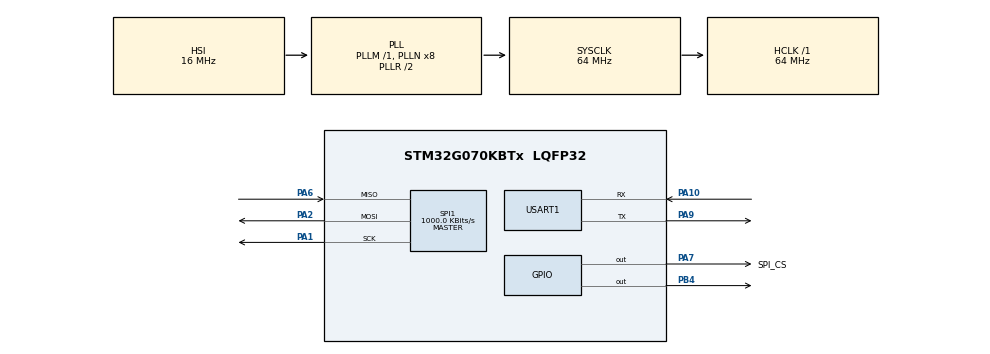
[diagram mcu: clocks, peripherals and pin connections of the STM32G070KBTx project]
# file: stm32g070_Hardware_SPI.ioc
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Dma.Request0=USART1_RX
Dma.Request1=USART1_TX
Dma.USART1_RX.0.Direction=DMA_PERIPH_TO_MEMORY
Dma.USART1_RX.0.EventEnable=DISABLE
Dma.USART1_RX.0.Instance=DMA1_Channel1
Dma.USART1_RX.0.MemDataAlignment=DMA_MDATAALIGN_BYTE
Dma.USART1_RX.0.MemInc=DMA_MINC_ENABLE
Dma.USART1_RX.0.Mode=DMA_CIRCULAR
Dma.USART1_RX.0.PeriphDataAlignment=DMA_PDATAALIGN_BYTE
Dma.USART1_RX.0.PeriphInc=DMA_PINC_DISABLE
Dma.USART1_RX.0.Polarity=HAL_DMAMUX_REQ_GEN_RISING
Dma.USART1_RX.0.Priority=DMA_PRIORITY_MEDIUM
Dma.USART1_RX.0.RequestNumber=1
Dma.USART1_RX.0.SignalID=NONE
Dma.USART1_RX.0.SyncEnable=DISABLE
Dma.USART1_RX.0.SyncPolarity=HAL_DMAMUX_SYNC_NO_EVENT
Dma.USART1_RX.0.SyncRequestNumber=1
Dma.USART1_RX.0.SyncSignalID=NONE
Dma.USART1_TX.1.Direction=DMA_MEMORY_TO_PERIPH
Dma.USART1_TX.1.EventEnable=DISABLE
Dma.USART1_TX.1.Instance=DMA1_Channel2
Dma.USART1_TX.1.MemDataAlignment=DMA_MDATAALIGN_BYTE
Dma.USART1_TX.1.MemInc=DMA_MINC_ENABLE
Dma.USART1_TX.1.Mode=DMA_NORMAL
Dma.USART1_TX.1.PeriphDataAlignment=DMA_PDATAALIGN_BYTE
Dma.USART1_TX.1.PeriphInc=DMA_PINC_DISABLE
Dma.USART1_TX.1.Polarity=HAL_DMAMUX_REQ_GEN_RISING
Dma.USART1_TX.1.Priority=DMA_PRIORITY_MEDIUM
Dma.USART1_TX.1.RequestNumber=1
Dma.USART1_TX.1.SignalID=NONE
Dma.USART1_TX.1.SyncEnable=DISABLE
Dma.USART1_TX.1.SyncPolarity=HAL_DMAMUX_SYNC_NO_EVENT
Dma.USART1_TX.1.SyncRequestNumber=1
Dma.USART1_TX.1.SyncSignalID=NONE
Mcu.Family=STM32G0
Mcu.Name=STM32G070KBTx
Mcu.Package=LQFP32
NVIC.DMA1_Channel1_IRQn=true\:0\:0\:false\:false\:true\:false\:true
NVIC.DMA1_Channel2_3_IRQn=true\:0\:0\:false\:false\:true\:false\:true
NVIC.USART1_IRQn=true\:0\:0\:false\:false\:true\:true\:true
PA1.GPIO_Mode=GPIO_MODE_AF_PP
PA1.GPIO_PuPd=GPIO_NOPULL
PA1.GPIO_Speed=GPIO_SPEED_FREQ_VERY_HIGH
PA1.Mode=Full_Duplex_Master
PA1.PinState=GPIO_PIN_RESET
PA1.Signal=SPI1_SCK
PA10.Mode=Asynchronous
PA10.Signal=USART1_RX
PA13.Mode=Serial_Wire
PA13.Signal=SYS_SWDIO
PA14-BOOT0.Mode=Serial_Wire
PA14-BOOT0.Signal=SYS_SWCLK
PA2.GPIO_Mode=GPIO_MODE_AF_PP
PA2.GPIO_PuPd=GPIO_NOPULL
PA2.GPIO_Speed=GPIO_SPEED_FREQ_VERY_HIGH
PA2.Mode=Full_Duplex_Master
PA2.PinState=GPIO_PIN_RESET
PA2.Signal=SPI1_MOSI
PA6.GPIO_Mode=GPIO_MODE_AF_PP
PA6.GPIO_PuPd=GPIO_NOPULL
PA6.GPIO_Speed=GPIO_SPEED_FREQ_VERY_HIGH
PA6.Mode=Full_Duplex_Master
PA6.PinState=GPIO_PIN_RESET
PA6.Signal=SPI1_MISO
PA7.GPIO_Label=SPI_CS
PA7.GPIO_Speed=GPIO_SPEED_FREQ_HIGH
PA7.Signal=GPIO_Output
PA9.Mode=Asynchronous
PA9.Signal=USART1_TX
PB4.GPIO_ModeDefaultOutputPP=GPIO_MODE_OUTPUT_PP
PB4.GPIO_PuPd=GPIO_NOPULL
PB4.GPIO_Speed=GPIO_SPEED_FREQ_LOW
PB4.PinState=GPIO_PIN_RESET
PB4.Signal=GPIO_Output
PC14-OSC32_IN\ (PC14).Mode=LSE-External-Oscillator
PC14-OSC32_IN\ (PC14).Signal=RCC_OSC32_IN
PC15-OSC32_OUT\ (PC15).Mode=LSE-External-Oscillator
PC15-OSC32_OUT\ (PC15).Signal=RCC_OSC32_OUT
ProjectManager.HeapSize=0x200
ProjectManager.StackSize=0x400
ProjectManager.TargetToolchain=Makefile
RCC.ADCFreq_Value=64000000
RCC.AHBFreq_Value=64000000
RCC.CortexFreq_Value=64000000
RCC.EXTERNAL_CLOCK_VALUE=48000
RCC.HCLKFreq_Value=64000000
RCC.HSE_VALUE=8000000
RCC.HSI_VALUE=16000000
RCC.SYSCLKFreq_VALUE=64000000
RCC.SYSCLKSource=RCC_SYSCLKSOURCE_PLLCLK
RCC.VCOOutputFreq_Value=128000000
SPI1.BaudRatePrescaler=SPI_BAUDRATEPRESCALER_64
SPI1.CalculateBaudRate=1000.0 KBits/s
SPI1.DataSize=SPI_DATASIZE_8BIT
SPI1.Direction=SPI_DIRECTION_2LINES
SPI1.Mode=SPI_MODE_MASTER
SPI1.VirtualType=VM_MASTER
USART1.VirtualMode-Asynchronous=VM_ASYNC
VP_SYS_VS_DBSignals.Mode=DisableDeadBatterySignals
board=custom

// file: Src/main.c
/* USER CODE BEGIN Header */
/**
  ******************************************************************************
  * @file           : main.c
  * @brief          : Main program body
  ******************************************************************************
  * @attention
  *
  * <h2><center>&copy; Copyright (c) 2020 STMicroelectronics.
  * All rights reserved.</center></h2>
  *
  * This software component is licensed by ST under BSD 3-Clause license,
  * the "License"; You may not use this file except in compliance with the
  * License. You may obtain a copy of the License at:
  *                        opensource.org/licenses/BSD-3-Clause
  *
  ******************************************************************************
  */
/* USER CODE END Header */

#include "main.h"
#include "dma.h"
#include "spi.h"
#include "usart.h"
#include "gpio.h"

/* USER CODE BEGIN Includes */
#include "oled.h"
/* USER CODE END Includes */

/* USER CODE BEGIN PV */
uint8_t Data[2]={0x55,0xaa};

/* USER CODE END PV */

void SystemClock_Config(void);

int main(void)
{

  /* MCU Configuration--------------------------------------------------------*/

  /* Reset of all peripherals, Initializes the Flash interface and the Systick. */
  HAL_Init();

  /* Configure the system clock */
  SystemClock_Config();

  /* Initialize all configured peripherals */
  MX_GPIO_Init();
  MX_DMA_Init();
  MX_SPI1_Init();
  MX_USART1_UART_Init();
  /* USER CODE BEGIN 2 */
	OLED_Init();
	OLED_Clear();
	OLED_ShowString(0,0,"receive:",16);
  /* USER CODE END 2 */

  /* Infinite loop */
  /* USER CODE BEGIN WHILE */
	//HAL_SPI_Transmit(&hspi1,Data,1,1000);//发送数据
  while (1)
  {
    /* USER CODE END WHILE */

    /* USER CODE BEGIN 3 */

	HAL_GPIO_WritePin(GPIOA,SPI_CS_Pin,GPIO_PIN_SET);		//片选使能

	HAL_SPI_Transmit(&hspi1,&Data[0],1,100);//发送数据
	HAL_SPI_Receive(&hspi1,&Data[1],1,0xFFFF);//接收数据
	OLED_ShowNum(72,0,Data[1],3,16);
	HAL_GPIO_TogglePin(GPIOB,GPIO_PIN_4);
	HAL_GPIO_WritePin(GPIOA,SPI_CS_Pin,GPIO_PIN_RESET);  	//片选不使能
	HAL_Delay(500);

  }
  /* USER CODE END 3 */
}

void SystemClock_Config(void)
{
  RCC_OscInitTypeDef RCC_OscInitStruct = {0};
  RCC_ClkInitTypeDef RCC_ClkInitStruct = {0};
  RCC_PeriphCLKInitTypeDef PeriphClkInit = {0};

  /** Configure the main internal regulator output voltage
  */
  HAL_PWREx_ControlVoltageScaling(PWR_REGULATOR_VOLTAGE_SCALE1);
  /** Initializes the CPU, AHB and APB busses clocks
  */
  RCC_OscInitStruct.OscillatorType = RCC_OSCILLATORTYPE_HSI;
  RCC_OscInitStruct.HSIState = RCC_HSI_ON;
  RCC_OscInitStruct.HSIDiv = RCC_HSI_DIV1;
  RCC_OscInitStruct.HSICalibrationValue = RCC_HSICALIBRATION_DEFAULT;
  RCC_OscInitStruct.PLL.PLLState = RCC_PLL_ON;
  RCC_OscInitStruct.PLL.PLLSource = RCC_PLLSOURCE_HSI;
  RCC_OscInitStruct.PLL.PLLM = RCC_PLLM_DIV1;
  RCC_OscInitStruct.PLL.PLLN = 8;
  RCC_OscInitStruct.PLL.PLLP = RCC_PLLP_DIV2;
  RCC_OscInitStruct.PLL.PLLR = RCC_PLLR_DIV2;
  if (HAL_RCC_OscConfig(&RCC_OscInitStruct) != HAL_OK)
  {
    Error_Handler();
  }
  /** Initializes the CPU, AHB and APB busses clocks
  */
  RCC_ClkInitStruct.ClockType = RCC_CLOCKTYPE_HCLK|RCC_CLOCKTYPE_SYSCLK
                              |RCC_CLOCKTYPE_PCLK1;
  RCC_ClkInitStruct.SYSCLKSource = RCC_SYSCLKSOURCE_PLLCLK;
  RCC_ClkInitStruct.AHBCLKDivider = RCC_SYSCLK_DIV1;
  RCC_ClkInitStruct.APB1CLKDivider = RCC_HCLK_DIV1;

  if (HAL_RCC_ClockConfig(&RCC_ClkInitStruct, FLASH_LATENCY_2) != HAL_OK)
  {
    Error_Handler();
  }
  /** Initializes the peripherals clocks
  */
  PeriphClkInit.PeriphClockSelection = RCC_PERIPHCLK_USART1;
  PeriphClkInit.Usart1ClockSelection = RCC_USART1CLKSOURCE_PCLK1;
  if (HAL_RCCEx_PeriphCLKConfig(&PeriphClkInit) != HAL_OK)
  {
    Error_Handler();
  }
}

void Error_Handler(void)
{
}

/************************ (C) COPYRIGHT STMicroelectronics *****END OF FILE****/
